# ADuCM302x register map
Vendor: Analog Devices; Series: ADuCM302x; File version: 1p0
CPU: CM3 r0p1, little endian, no MPU, no FPU, 3 interrupt priority bits
Registers are 32-bit, read-write, reset 0x0 unless marked. A register's access mark holds for its fields unless they carry their own. Offsets are from the block's base; [hi:lo] are bit positions; 'fields as' and 'values as' point back to an identical list.

## SYS — System Identification and Debug Enable
Base 0x40002000
0x20 ADIID 16-bit reset 0x4144 — ADI Identification
  [15:0] VALUE ro — Reads a fixed value of 0x4144 to indicate to debuggers that they are connected to an Analog Devices implemented Cortex based part
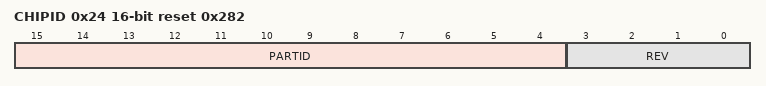
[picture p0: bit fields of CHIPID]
0x24 CHIPID 16-bit reset 0x282 — Chip Identifier
  [15:4] PARTID ro — Part identifier
  [3:0] REV ro — Silicon revision
0x40 SWDEN 16-bit reset 0x7072 — Serial Wire Debug Enable
  [15:0] VALUE wo range 0x00000000..0x0000FFFF — To enable SWD interface

## WDT0 — Watchdog Timer
Base 0x40002C00
0x00 LOAD 16-bit reset 0x1000 — Load Value
  [15:0] VALUE range 0x00000000..0x0000FFFF — Load value
0x04 CCNT 16-bit reset 0x1000 — Current Count Value
  [15:0] VALUE ro — Current count value
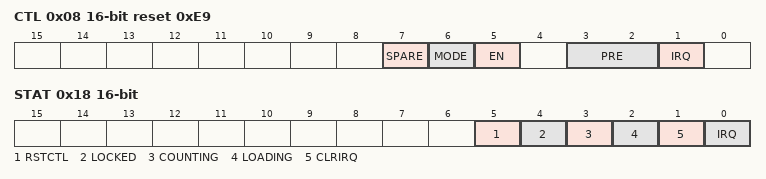
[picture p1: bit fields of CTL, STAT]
0x08 CTL 16-bit reset 0xE9 — Control
  [7] SPARE range 0x00000000..0x00000001 — Spare bit (unused)
  [6] MODE range 0x00000000..0x00000001 — Timer mode
  [5] EN range 0x00000000..0x00000001 — Timer enable
  [3:2] PRE — Prescaler
    0=div1 (source clock/1); 1=div16 (source clock/16); 2=div256 (source clock/256 (default))
  [1] IRQ range 0x00000000..0x00000001 — Timer interrupt
0x0C RESTART 16-bit — Clear Interrupt
  [15:0] CLRWORD wo range 0x00000000..0x0000FFFF — Clear watchdog
0x18 STAT 16-bit — Status
  [5] RSTCTL ro — Reset Control Register written and locked
  [4] LOCKED ro — Lock status bit
  [3] COUNTING ro — Control Register write sync in progress
  [2] LOADING ro — Load Register write sync in progress
  [1] CLRIRQ ro — Clear Interrupt Register write sync in progress
  [0] IRQ ro — WDT Interrupt

## BEEP0 — Beeper Driver
Base 0x40005C00
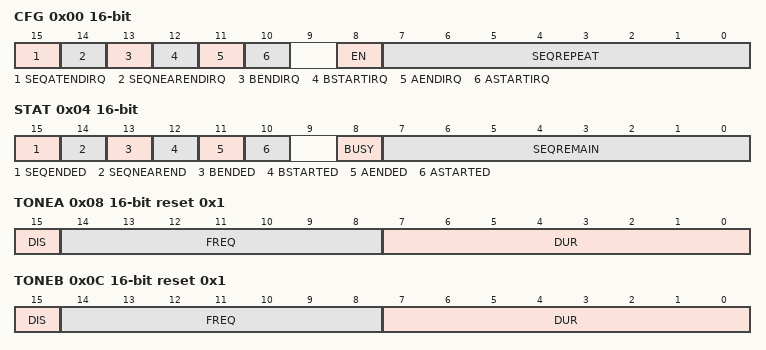
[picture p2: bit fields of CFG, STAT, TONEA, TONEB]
0x00 CFG 16-bit — Beeper configuration
  [15] SEQATENDIRQ — Sequence end IRQ
  [14] SEQNEARENDIRQ — Sequence 1 cycle from end IRQ
  [13] BENDIRQ — Tone B end IRQ
  [12] BSTARTIRQ — Tone B start IRQ
  [11] AENDIRQ — Tone A end IRQ
  [10] ASTARTIRQ — Tone A start IRQ
  [8] EN — Beeper Enable
  [7:0] SEQREPEAT — Beeper Sequence Repeat value
0x04 STAT 16-bit — Beeper status
  [15] SEQENDED range 0x00000000..0x00000001 — Sequencer has ended
  [14] SEQNEAREND range 0x00000000..0x00000001 — Sequencer last tone-pair has started
  [13] BENDED range 0x00000000..0x00000001 — Tone B has ended
  [12] BSTARTED range 0x00000000..0x00000001 — Tone B has started
  [11] AENDED range 0x00000000..0x00000001 — Tone A has ended
  [10] ASTARTED range 0x00000000..0x00000001 — Tone A has started
  [8] BUSY ro — Beeper is busy
  [7:0] SEQREMAIN ro — Remaining tone-pair sequence iterations to play in SEQ mode
0x08 TONEA 16-bit reset 0x1 — Tone A Data
  [15] DIS — Output disable
  [14:8] FREQ — Tone frequency
  [7:0] DUR — Tone duration
0x0C TONEB 16-bit reset 0x1 — Tone B Data
  fields as TONEA

## DMA0 — DMA
Base 0x40010000
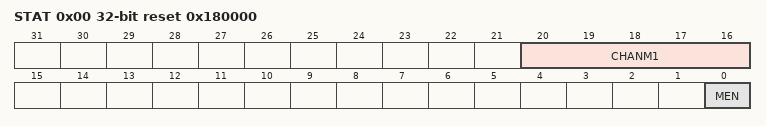
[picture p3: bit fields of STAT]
0x00 STAT reset 0x180000 — DMA Status
  [20:16] CHANM1 ro — Number of available DMA channels minus 1
  [0] MEN ro — Enable status of the controller
0x04 CFG — DMA Configuration
  [0] MEN wo — Controller enable
0x08 PDBPTR — DMA Channel Primary Control Database Pointer
  [31:0] ADDR range 0x00000000..0xFFFFFFFF — Pointer to the base address of the primary data structure
0x0C ADBPTR reset 0x200 — DMA Channel Alternate Control Database Pointer
  [31:0] ADDR ro — Base address of the alternate data structure
0x14 SWREQ — DMA Channel Software Request
  [24:0] CHAN wo range 0x00000000..0x01FFFFFF — Generate software request
0x20 RMSK_SET — DMA Channel Request Mask Set
  [24:0] CHAN range 0x00000000..0x01FFFFFF — Mask requests from DMA channels
0x24 RMSK_CLR — DMA Channel Request Mask Clear
  [24:0] CHAN wo range 0x00000000..0x01FFFFFF — Clear Request Mask Set bits
0x28 EN_SET — DMA Channel Enable Set
  [24:0] CHAN range 0x00000000..0x01FFFFFF — Enable DMA channels
0x2C EN_CLR — DMA Channel Enable Clear
  [24:0] CHAN wo range 0x00000000..0x01FFFFFF — Disable DMA channels
0x30 ALT_SET — DMA Channel Primary Alternate Set
  [24:0] CHAN range 0x00000000..0x01FFFFFF — Control structure status / Select alternate structure
0x34 ALT_CLR — DMA Channel Primary Alternate Clear
  [24:0] CHAN wo range 0x00000000..0x01FFFFFF — Select primary data structure
0x38 PRI_SET — DMA Channel Priority Set
  [24:0] CHAN wo range 0x00000000..0x01FFFFFF — Configure channel for high priority
0x3C PRI_CLR — DMA Channel Priority Clear
  [24:0] CHPRICLR wo range 0x00000000..0x01FFFFFF — Configure channel for default priority level
0x48 ERRCHNL_CLR — DMA Per Channel Error Clear
  [24:0] CHAN range 0x00000000..0x01FFFFFF — Per channel Bus error status/clear
0x4C ERR_CLR — DMA Bus Error Clear
  [24:0] CHAN range 0x00000000..0x01FFFFFF — Bus error status
0x50 INVALIDDESC_CLR — DMA Per Channel Invalid Descriptor Clear
  [24:0] CHAN range 0x00000000..0x01FFFFFF — Per channel Invalid Descriptor Status/Clear
0x800 BS_SET — DMA Channel Bytes Swap Enable Set
  [24:0] CHAN range 0x00000000..0x01FFFFFF — Byte swap status
0x804 BS_CLR — DMA Channel Bytes Swap Enable Clear
  [24:0] CHAN wo range 0x00000000..0x01FFFFFF — Disable byte swap
0x810 SRCADDR_SET — DMA Channel Source Address Decrement Enable Set
  [24:0] CHAN range 0x00000000..0x01FFFFFF — Source Address decrement status / configure Source address decrement
0x814 SRCADDR_CLR — DMA Channel Source Address Decrement Enable Clear
  [24:0] CHAN wo range 0x00000000..0x01FFFFFF — Disable source address decrement
0x818 DSTADDR_SET — DMA Channel Destination Address Decrement Enable Set
  [24:0] CHAN range 0x00000000..0x01FFFFFF — Destination Address decrement status / configure destination address decrement
0x81C DSTADDR_CLR — DMA Channel Destination Address Decrement Enable Clear
  [24:0] CHAN wo range 0x00000000..0x01FFFFFF — Disable destination address decrement
0xFE0 REVID reset 0x2 — DMA Controller Revision ID
  [7:0] VALUE ro — DMA Controller revision ID
